# EOS-S3 register map
File version: 0.1
CPU: CM4 r0p1, selectable endian, MPU, FPU, 3 interrupt priority bits
Registers are 32-bit, read-write, reset 0x0 unless marked. A register's access mark holds for its fields unless they carry their own. Offsets are from the block's base; [hi:lo] are bit positions; {n}, {i} and the like mark numbered series.

## EXTM4Regs — External registers to control M4 Subsystem (not a core peripheral)
Base 0x40000000
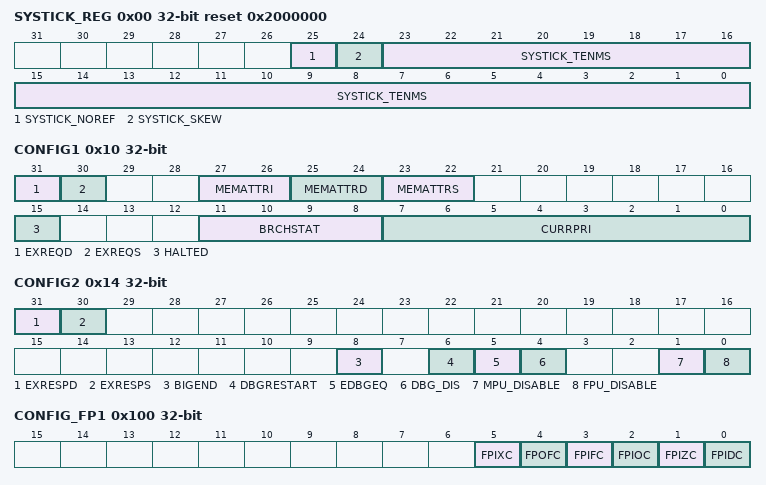
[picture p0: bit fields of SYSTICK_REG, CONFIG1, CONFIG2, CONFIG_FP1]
0x00 SYSTICK_REG reset 0x2000000 — System tick timer register
  [25] SYSTICK_NOREF — Indicates that no alternative reference clock source has been integrated.
  [24] SYSTICK_SKEW — Systick clock is an exact multiple of 10ms
  [23:0] SYSTICK_TENMS — Provides an integer value to compute a 10ms (100Hz) delay. For example, apply the value 0x07A11F if no reference is implemented, and FCLK is 50MHz.
0x10 CONFIG1 ro — Configuration register 1
  [31] EXREQD — Exclusive Request. EXREQD is an address phase control signal that indicates if the access is because of a LDREX or STREX: . 0 = No request . 1 = Exclusive request. . You can use EXREQD and EXRESPD to synchronize primitives and semaphores.
  [30] EXREQS — Exclusive Request. EXREQS is an address phase control signal that indicates if the access is because of a LDREX or STREX: . 0 = No request . 1 = Exclusive request . You can use EXREQS and EXRESPS to synchronize primitives and semaphores.
  [27:26] MEMATTRI — Memory attributes. Always 0b01 for this bus. They are always Non-shareable, Non-allocate.
  [25:24] MEMATTRD — Memory attributes. Always 0b01 for this bus. They are always Non-shareable, Non-allocate.
  [23:22] MEMATTRS — Memory Attributes. . Bit 0 = Allocate . Bit 1 = Shareable.
  [15] HALTED — In halting mode debug. HALTED remains asserted while the core is in debug.
  [11:8] BRCHSTAT — Branch status
    0=no_hint; 1=cond_backwards_decode (Conditional branch backwards in decode); 2=cond_decode (Conditional branch in decode); 3=cond_execute (Conditional branch in execute); 4=uncond_decode (Unconditional branch in decode); 5=uncond_execute (Unconditional branch in execute); 8=cond_decode_taken (Conditional branch in decode taken (cycle after IHTRANS))
  [7:0] CURRPRI — Indicates what priority interrupt, or base boost, is being used now. CURRPRI represents the preemption priority, and does not indicate secondary priority.
0x14 CONFIG2 — Configuration register 2
  [31] EXRESPD — Exclusive Response. EXRESPD is a data phase response like HRESPD, but is only valid for exclusive accesses and indicates the success or failure of an exclusive operation: . 0 = Exclusive request accepted . 1 = Exclusive request failed. . You can use EXREQD and EXRESPD to synchronize primitives and semaphores.
  [30] EXRESPS — Exclusive Response. EXRESPS is a data phase response like HRESPS, but is only valid for exclusive accesses and indicates the success or failure of an exclusive operation: . 0 = Exclusive request accepted . 1 = Exclusive request failed. . You can use EXREQS and EXRESPS to synchronize primitives and semaphores.
  [8] BIGEND — Static endianness setting. This signal is sampled at reset, and cannot be changed when reset is inactive.
    0=little_endian (Select little endian as endiannes setting); 1=big_endian (Select big endian as endiannes setting)
  [6] DBGRESTART — Debugger restart. Internal use only
  [5] EDBGEQ — External debug request. Internal use only
  [4] DBG_DIS — Set to disable the M4 debugger
  [1] MPU_DISABLE — Set to disable de Memory Protection Unit
  [0] FPU_DISABLE — Set to disable the Floating Point Arithmetic Unit
0x100 CONFIG_FP1 ro — FPU configuration register 1
  [5] FPIXC — Floating-point inexact exception
  [4] FPOFC — Floating-point overflow exception
  [3] FPIFC — Floating-point underflow exception
  [2] FPIOC — Floating-point invalid exception
  [1] FPIZC — Floating-point divide-by-zero exception
  [0] FPIDC — Floating-point input denormal exception
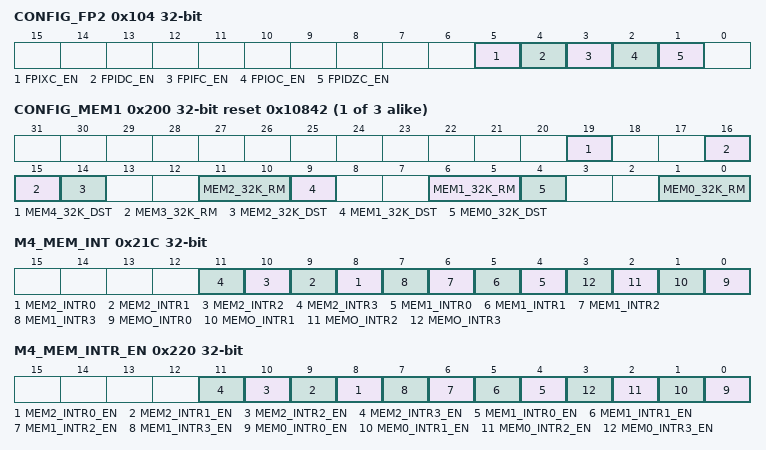
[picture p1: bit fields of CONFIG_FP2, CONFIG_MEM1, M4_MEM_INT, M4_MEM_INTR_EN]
0x104 CONFIG_FP2 — FPU configuration register 2
  [5] FPIXC_EN — Mask exception to cpu; Floating-point inexact exception
  [4] FPIDC_EN — Mask exception to cpu; Floating-point overflow exception
  [3] FPIFC_EN — Mask exception to cpu; Floating-point underflow exception
  [2] FPIOC_EN — Mask exception to cpu; Floating-point invalid operation exception
  [1] FPIDZC_EN — Mask exception to cpu; Floating-point divide-by-zero exception
{0x1FC+4i} CONFIG_MEM{i} reset 0x10842 (i=1..3) — Memory configuration register {i}
  [19] MEM4_32K_DST — ‘Disable-Self-Time’. When asserted high, overrides the self-timed circuitry and causes the read margin to be controlled by the falling clk edge. Requires margin[] to be set to 2’b00. This pin is intended for debug/FA purposes only.
  [5n+1:5n] MEM{n}_32K_RM (n=0..3) — Read and write margin control. Recommended setting is 2’b10. 2’b00 provides the most margin (slowest speed). 2’b11 provides the least margin (fastest speed) memory. This setting is required for VDDMIN operation.
  [14] MEM2_32K_DST — ‘Disable-Self-Time’. When asserted high, overrides the self-timed circuitry and causes the read margin to be controlled by the falling clk edge. Requires margin[] to be set to 2’b00. This pin is intended for debug/FA purposes only.
  [9] MEM1_32K_DST — ‘Disable-Self-Time’. When asserted high, overrides the self-timed circuitry and causes the read margin to be controlled by the falling clk edge. Requires margin[] to be set to 2’b00. This pin is intended for debug/FA purposes only.
  [4] MEM0_32K_DST — ‘Disable-Self-Time’. When asserted high, overrides the self-timed circuitry and causes the read margin to be controlled by the falling clk edge. Requires margin[] to be set to 2’b00. This pin is intended for debug/FA purposes only.
0x21C M4_MEM_INT — SRAM access while in low power mode interrupt flag register (Set bit to clear)
  [n+8] MEM2_INTR{n} (n=0..3) — Interrupt caused by a SRAM access (M4 SRAM segment 2 32KB_{n}) while it in deep sleep or shut down mode
  [n+4] MEM1_INTR{n} (n=0..3) — Interrupt caused by a SRAM access (M4 SRAM segment 1 32KB_{n}) while it in deep sleep or shut down mode
  [n] MEMO_INTR{n} (n=0..3) — Interrupt caused by a SRAM access (M4 SRAM segment 0 32KB_{n}) while it in deep sleep or shut down mode
0x220 M4_MEM_INTR_EN — SRAM memory access while M4 in low power mode interrupts enable register
  [n+8] MEM2_INTR{n}_EN (n=0..3) — Interrupt enable (M4 SRAM segment 2 32KB_{n})
  [n+4] MEM1_INTR{n}_EN (n=0..3) — Interrupt enable (M4 SRAM segment 1 32KB_{n})
  [n] MEM0_INTR{n}_EN (n=0..3) — Interrupt enable (M4 SRAM segment 0 32KB_{n})
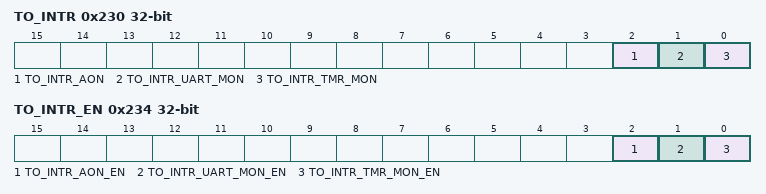
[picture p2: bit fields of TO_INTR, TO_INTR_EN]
0x230 TO_INTR — No description provided
  [2] TO_INTR_AON, [1] TO_INTR_UART_MON, [0] TO_INTR_TMR_MON
0x234 TO_INTR_EN — No description provided
  [2] TO_INTR_AON_EN, [1] TO_INTR_UART_MON_EN, [0] TO_INTR_TMR_MON_EN
0x250 A1_POWER_STAT — Status of the A1 subsystem power status
  [1:0] A1_POWER_STAT ro
0x300 FB_RAMFIFO — Sets Fabric in APB mode
  [0] FB_RAMFIFO_MODE
